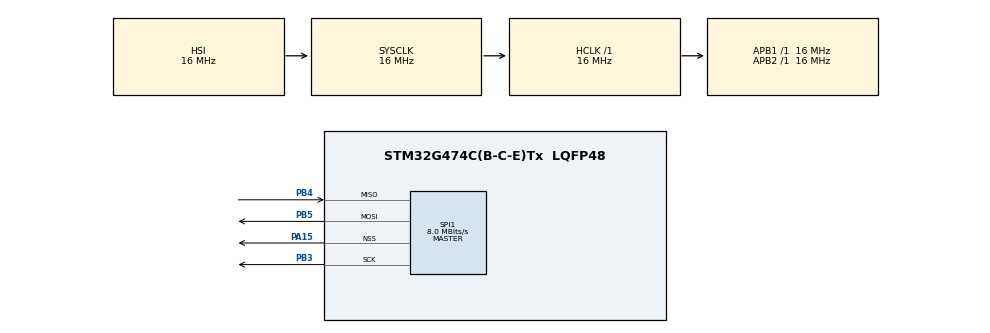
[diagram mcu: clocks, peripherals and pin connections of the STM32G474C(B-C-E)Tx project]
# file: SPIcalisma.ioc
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Mcu.Family=STM32G4
Mcu.Name=STM32G474C(B-C-E)Tx
Mcu.Package=LQFP48
NVIC.PriorityGroup=NVIC_PRIORITYGROUP_4
PA15.Mode=NSS_Signal_Hard_Output
PA15.Signal=SPI1_NSS
PB3.Mode=Full_Duplex_Master
PB3.Signal=SPI1_SCK
PB4.Mode=Full_Duplex_Master
PB4.Signal=SPI1_MISO
PB5.Mode=Full_Duplex_Master
PB5.Signal=SPI1_MOSI
PC14-OSC32_IN.Mode=LSE-External-Oscillator
PC14-OSC32_IN.Signal=RCC_OSC32_IN
PC15-OSC32_OUT.Mode=LSE-External-Oscillator
PC15-OSC32_OUT.Signal=RCC_OSC32_OUT
PF0-OSC_IN.Mode=HSE-External-Oscillator
PF0-OSC_IN.Signal=RCC_OSC_IN
PF1-OSC_OUT.Mode=HSE-External-Oscillator
PF1-OSC_OUT.Signal=RCC_OSC_OUT
ProjectManager.HeapSize=0x200
ProjectManager.StackSize=0x400
ProjectManager.TargetToolchain=STM32CubeIDE
RCC.AHBFreq_Value=16000000
RCC.APB1Freq_Value=16000000
RCC.APB1TimFreq_Value=16000000
RCC.APB2Freq_Value=16000000
RCC.APB2TimFreq_Value=16000000
RCC.CortexFreq_Value=16000000
RCC.EXTERNAL_CLOCK_VALUE=12288000
RCC.HCLKFreq_Value=16000000
RCC.HSE_VALUE=8000000
RCC.HSI48_VALUE=48000000
RCC.HSI_VALUE=16000000
RCC.SYSCLKFreq_VALUE=16000000
RCC.USBFreq_Value=64000000
RCC.VCOOutputFreq_Value=128000000
SPI1.CalculateBaudRate=8.0 MBits/s
SPI1.Direction=SPI_DIRECTION_2LINES
SPI1.Mode=SPI_MODE_MASTER
SPI1.VirtualNSS=VM_NSSHARD
SPI1.VirtualType=VM_MASTER
VP_SYS_VS_DBSignals.Mode=DisableDeadBatterySignals
board=custom

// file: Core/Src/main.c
/* USER CODE BEGIN Header */
/**
  ******************************************************************************
  * @file           : main.c
  * @brief          : Main program body
  ******************************************************************************
  * @attention
  *
  * Copyright (c) 2025 STMicroelectronics.
  * All rights reserved.
  *
  * This software is licensed under terms that can be found in the LICENSE file
  * in the root directory of this software component.
  * If no LICENSE file comes with this software, it is provided AS-IS.
  *
  ******************************************************************************
  */
/* USER CODE END Header */
#include "main.h"

SPI_HandleTypeDef hspi1;

void SystemClock_Config(void);
static void MX_GPIO_Init(void);
static void MX_SPI1_Init(void);

int main(void)
{

  /* MCU Configuration--------------------------------------------------------*/

  /* Reset of all peripherals, Initializes the Flash interface and the Systick. */
  HAL_Init();

  /* Configure the system clock */
  SystemClock_Config();

  /* Initialize all configured peripherals */
  MX_GPIO_Init();
  MX_SPI1_Init();

  /* Infinite loop */
  while (1)
  {

    /* USER CODE BEGIN 3 */

  HAL_SPI_Transmit(&hspi1, pData, Size, Timeout);

  }
  /* USER CODE END 3 */
}

void SystemClock_Config(void)
{
  RCC_OscInitTypeDef RCC_OscInitStruct = {0};
  RCC_ClkInitTypeDef RCC_ClkInitStruct = {0};

  /** Configure the main internal regulator output voltage
  */
  HAL_PWREx_ControlVoltageScaling(PWR_REGULATOR_VOLTAGE_SCALE1);

  /** Initializes the RCC Oscillators according to the specified parameters
  * in the RCC_OscInitTypeDef structure.
  */
  RCC_OscInitStruct.OscillatorType = RCC_OSCILLATORTYPE_HSI;
  RCC_OscInitStruct.HSIState = RCC_HSI_ON;
  RCC_OscInitStruct.HSICalibrationValue = RCC_HSICALIBRATION_DEFAULT;
  RCC_OscInitStruct.PLL.PLLState = RCC_PLL_NONE;
  if (HAL_RCC_OscConfig(&RCC_OscInitStruct) != HAL_OK)
  {
    Error_Handler();
  }

  /** Initializes the CPU, AHB and APB buses clocks
  */
  RCC_ClkInitStruct.ClockType = RCC_CLOCKTYPE_HCLK|RCC_CLOCKTYPE_SYSCLK
                              |RCC_CLOCKTYPE_PCLK1|RCC_CLOCKTYPE_PCLK2;
  RCC_ClkInitStruct.SYSCLKSource = RCC_SYSCLKSOURCE_HSI;
  RCC_ClkInitStruct.AHBCLKDivider = RCC_SYSCLK_DIV1;
  RCC_ClkInitStruct.APB1CLKDivider = RCC_HCLK_DIV1;
  RCC_ClkInitStruct.APB2CLKDivider = RCC_HCLK_DIV1;

  if (HAL_RCC_ClockConfig(&RCC_ClkInitStruct, FLASH_LATENCY_0) != HAL_OK)
  {
    Error_Handler();
  }
}

static void MX_SPI1_Init(void)
{

  /* SPI1 parameter configuration*/
  hspi1.Instance = SPI1;
  hspi1.Init.Mode = SPI_MODE_MASTER;
  hspi1.Init.Direction = SPI_DIRECTION_2LINES;
  hspi1.Init.DataSize = SPI_DATASIZE_4BIT;
  hspi1.Init.CLKPolarity = SPI_POLARITY_LOW;
  hspi1.Init.CLKPhase = SPI_PHASE_1EDGE;
  hspi1.Init.NSS = SPI_NSS_HARD_OUTPUT;
  hspi1.Init.BaudRatePrescaler = SPI_BAUDRATEPRESCALER_2;
  hspi1.Init.FirstBit = SPI_FIRSTBIT_MSB;
  hspi1.Init.TIMode = SPI_TIMODE_DISABLE;
  hspi1.Init.CRCCalculation = SPI_CRCCALCULATION_DISABLE;
  hspi1.Init.CRCPolynomial = 7;
  hspi1.Init.CRCLength = SPI_CRC_LENGTH_DATASIZE;
  hspi1.Init.NSSPMode = SPI_NSS_PULSE_ENABLE;
  if (HAL_SPI_Init(&hspi1) != HAL_OK)
  {
    Error_Handler();
  }

}

static void MX_GPIO_Init(void)
{

  /* GPIO Ports Clock Enable */
  __HAL_RCC_GPIOC_CLK_ENABLE();
  __HAL_RCC_GPIOF_CLK_ENABLE();
  __HAL_RCC_GPIOA_CLK_ENABLE();
  __HAL_RCC_GPIOB_CLK_ENABLE();

}

void Error_Handler(void)
{
  __disable_irq();
  while (1)
  {
  }
}
